# cslr_gpio_001 register map
Vendor: Texas Instruments
Peripheral module from a debugger description file (folder C5505).
Address unit: 16 bits
Registers are 16-bit, read-write, reset 0x0 unless marked. A register's access mark holds for its fields unless they carry their own. Offsets are as the file gives them; lines under a group give offsets from that group; [hi:lo] are bit positions; {n}, {i} and the like mark numbered series; 'fields as' and 'values as' point back to an identical list; <NAME> marks a mode.

## GPIO — General Purpose Input Output
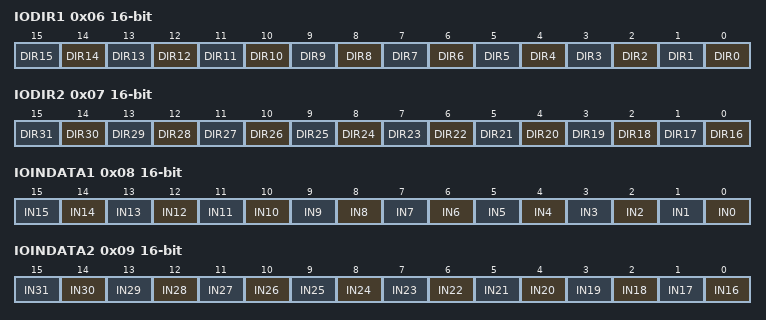
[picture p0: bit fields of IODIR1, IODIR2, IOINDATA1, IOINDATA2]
0x06 IODIR1 — GPIO data direction bits that configure the general purpose IO pins 0 - 15 as either inputs or outputs
  [all] fields
    0=Clear; 1=Set
  [n] DIR{n} (n=0..15) — Direction of GPIO Pin {n}
0x07 IODIR2 — GPIO data direction bits that configure the general purpose IO pins 16 - 31 as either inputs or outputs
  [all] fields
    0=Clear; 1=Set
  [n-16] DIR{n} (n=16..31) — Direction of GPIO Pin {n}
0x08 IOINDATA1 ro — Data bits used to monitor the state of GPIO pins 0 -15 when configured as inputs.
  [all] fields
    0=Clear (Input is low); 1=Set (Input is High)
  [n] IN{n} (n=0..15) — Status of GPIO Bit {n}
0x09 IOINDATA2 ro — Data bits used to monitor the state of GPIO pins 16 - 31 when configured as inputs.
  [all] fields
    0=Clear (Input is low); 1=Set (Input is High)
  [n-16] IN{n} (n=16..31) — Status of GPIO Bit {n}
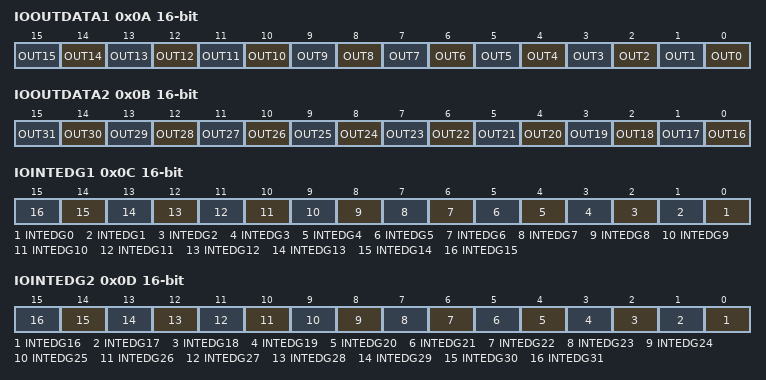
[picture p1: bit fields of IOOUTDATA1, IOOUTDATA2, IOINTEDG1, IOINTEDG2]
0x0A IOOUTDATA1 — Data bits used to control the level of the GPIO pins 0 - 15 which are set as outputs
  [all] fields
    0=Clear (Ouput is low); 1=Set (Output is High)
  [n] OUT{n} (n=0..15) — output control for GPIO {n}
0x0B IOOUTDATA2 — Data bits used to control the level of the GPIO pins 16 - 31 which are set as outputs
  [all] fields
    0=Clear (Ouput is low); 1=Set (Output is High)
  [n-16] OUT{n} (n=16..31) — output control for GPIO {n}
0x0C IOINTEDG1 — Data bits used to set the Interrupt trigger of GPIO pins 0 - 15 to rising or falling edge if the GPIO has interrupt enabled. 0 = rising edge; 1 = falling edge
  [all] fields
    0=Clear (Rising edge triggered); 1=Set (Falling edge triggered)
  [n] INTEDG{n} (n=0..15) — Edge select for GPIO {n}
0x0D IOINTEDG2 — Data bits used to set the Interrupt trigger of GPIO pins 16 - 31 to rising or falling edge if the GPIO has interrupt enabled. 0 = rising edge; 1 = falling edge
  [all] fields
    values as the fields of IOINTEDG1
  [n-16] INTEDG{n} (n=16..31) — Edge select for GPIO {n}
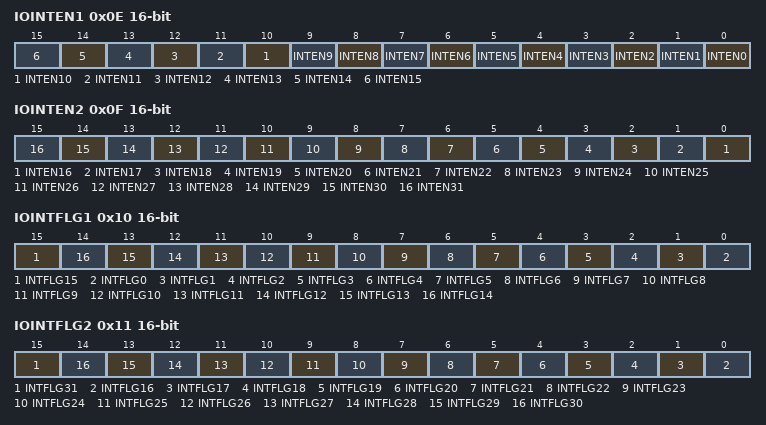
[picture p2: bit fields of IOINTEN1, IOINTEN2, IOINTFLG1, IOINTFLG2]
0x0E IOINTEN1 — Data bits used to enable the Interrupts of GPIO pins 0 - 15. 0 = Interrupt disabled; 1 = Interrupt enabled.
  [all] fields
    0=Clear (Interrupt disabled); 1=Set (Interrupt enabled)
  [n] INTEN{n} (n=0..15) — Interrupt enable for GPIO {n}
0x0F IOINTEN2 — Data bits used to enable the Interrupts of GPIO pins 16 - 31. 0 = Interrupt disabled; 1 = Interrupt enabled.
  [all] fields
    0=Clear (Interrupt disabled); 1=Set (Interrupt enabled)
  [n-16] INTEN{n} (n=16..31) — Interrupt enable for GPIO {n}
0x10 IOINTFLG1 — Data bits used to monitor which GPIO Interrupt was triggered. For GPIO pins 0 - 15
  [all] fields
    0=Clear (No Interrupt occurred); 1=Set (Interrupt occurred (if 1 is written then the flag is cleared))
  [15] INTFLG15 — This register latches the corresponding I/O pin(s) that triggered an interrupt. The flag is cleared by setting the corresponding bit. The interrut signal to the CPU will be kept low until all flag bits are cleared.
  [n] INTFLG{n} (n=0..14)
0x11 IOINTFLG2 — Data bits used to monitor which GPIO Interrupt was triggered for GPIO pins 16 - 31.
  [all] fields
    values as the fields of IOINTFLG1
  [15] INTFLG31 — This register latches the corresponding I/O pin(s) that triggered an interrupt. The flag is cleared by setting the corresponding bit. The interrut signal to the CPU will be kept low until all flag bits are cleared.
  [n-16] INTFLG{n} (n=16..30)
